# mcr_me12 register map
Registers are access not given, no defined reset value unless marked. A register's access mark holds for its fields unless they carry their own. Offsets are from the block's base; lines under a group give offsets from that group; [hi:lo] are bit positions; {n}, {i} and the like mark numbered series; 'fields as' and 'values as' point back to an identical list; <NAME> marks a mode.

## Memory map
0x40006C00 MCR size 0x400 — Misc Control.

## MCR — Misc Control.
Base 0x40006C00
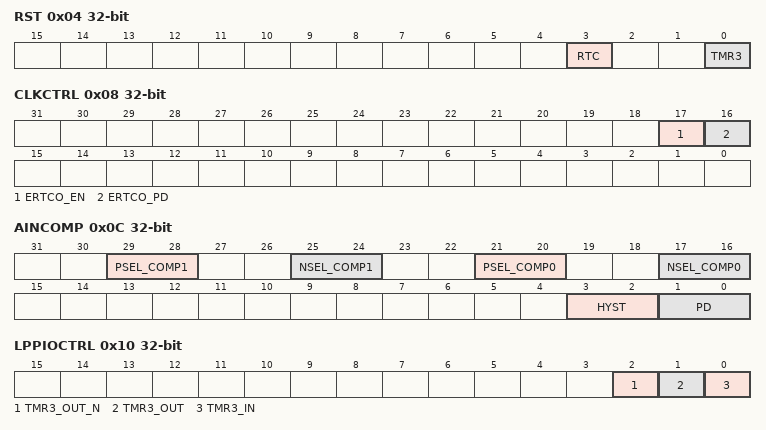
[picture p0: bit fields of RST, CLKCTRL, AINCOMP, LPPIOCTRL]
0x04 RST — Reset Register.
  [3] RTC — Real Time Clock Reset.
  [0] TMR3 — TMR3 (LPTMR0) Reset. Setting this bit to 1 resets TMR3 (LPTMR0) block.
0x08 CLKCTRL — System CLock Control Register.
  [17] ERTCO_EN — 32kHz Crystal Oscillator Enable.
  [16] ERTCO_PD — 32kHz Crystal Oscillator Power Down. Setting this bit powers down the ERTCO analog circuitry.
0x0C AINCOMP — AIN Comparator Control Register.
  [29:28] PSEL_COMP1 — Positive input select for AIN Comparator 1. No more than 1 input channel can be selected at any time. Corresponding GPIO must be configured for AF4.
  [25:24] NSEL_COMP1 — Negative input select for Comparator 1. No more than 1 input channel can be selected at any time. Corresponding GPIO must be configured for AF4.
  [21:20] PSEL_COMP0 — Positive input select for AIN Comparator 0. No more than 1 input channel can be selected at any time. Corresponding GPIO must be configured for AF4.
  [17:16] NSEL_COMP0 — Negative input select for Comparator 0. No more than 1 input channel can be selected at any time. Corresponding GPIO must be configured for AF4.
  [3:2] HYST — AIN Comparator Hysteresis control.
  [1:0] PD — AIN Compatator Power Down control. Before AIN Comparator is powered on, the positive and negative inputs selects for the comparator should be configured.
0x10 LPPIOCTRL — Low Power Peripheral IO Control Register.
  [2] TMR3_OUT_N — Enable control for TMR3 (LPTMR0) complementary output. If enabled and peripheral clock also enabled (PCLKDIS.TMR3), the peripheral output controls the associated GPIO in output mode; otherwise GPIO control comes from GPIO control module
  [1] TMR3_OUT — Enable control for LPTMR0 output. If enabled and peripheral clock also enabled (PCLKDIS.LPTMR0), the peripheral output controls the associated GPIO in output mode; otherwise GPIO control comes from GPIO control module.
  [0] TMR3_IN — Enable control for TMR3 (LPTMR0) input. If enabled, the associated GPIO input is connected to the peripheral; otherwise the input to the peripheral is forced low.
0x24 PCLKDIS — Peripheral Clock Disable Register.
  [0] TMR3 — TMR3 (LPTMR0) Clock Disable.
0x34 AESKEY — AES Key Pointer and Status Register.
  [15:0] PTR — AES Key Pointer/Status
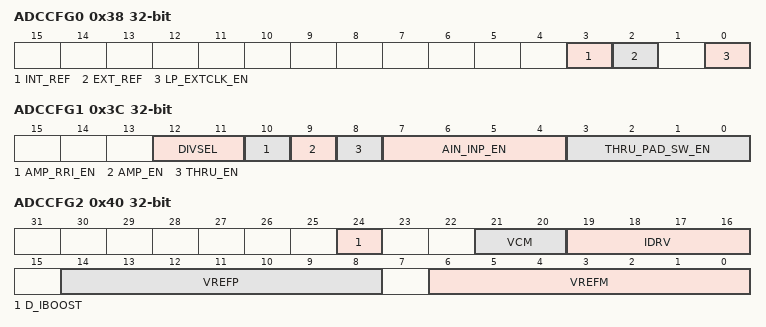
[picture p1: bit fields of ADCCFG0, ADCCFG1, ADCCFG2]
0x38 ADCCFG0 — ADC Config Register 0.
  [3] INT_REF — Internal Reference Select Option, when not using External Reference.
  [2] EXT_REF — External Reference Select.
  [0] LP_EXTCLK_EN — Enable input driver for LP External Clock.
0x3C ADCCFG1 — ADC Config Register 1.
  [12:11] DIVSEL — Select one of the three different signal paths.
  [10] AMP_RRI_EN — Enable the buffer amplifier to operatore for Rail to Rail Input, Active High. If it is low, only NMOS Input pair will be operating which would restrict the range,
  [9] AMP_EN — Enable the buffer amplifier used in the buffer path.
  [8] THRU_EN — Enable the MUX switches, switch placed in analog_sys, used in the buffer path.
  [7:4] AIN_INP_EN — AIN Input Enable.
  [3:0] THRU_PAD_SW_EN — Enable the MUX switch, switch placed in padring, used in the buffer path. Each pad has a separate THRU_PAD_SW_EN signal.
0x40 ADCCFG2 — ADC Config Register 2.
  [24] D_IBOOST — Trimming value for extra drive current in reference buffer outputs
  [21:20] VCM — Trimming code for VCM output of reference buffer.
  [19:16] IDRV — Trimming code for reference buffer drive strength.
  [14:8] VREFP — Trimming code for VREFP output of reference buffer.
  [6:0] VREFM — Trimming code for VREFM output of reference buffer.
